# netx90_app register map
File version: 1.0
CPU: CM4 r0p1, little endian, MPU, FPU, 4 interrupt priority bits, 78 interrupts
Registers are 32-bit, read-write, reset 0x0 unless marked. A register's access mark holds for its fields unless they carry their own. Offsets are from the block's base; [hi:lo] are bit positions; {n}, {i} and the like mark numbered series; 'fields as' and 'values as' point back to an identical list.

## hif_io_ctrl
Base 0xFF401480
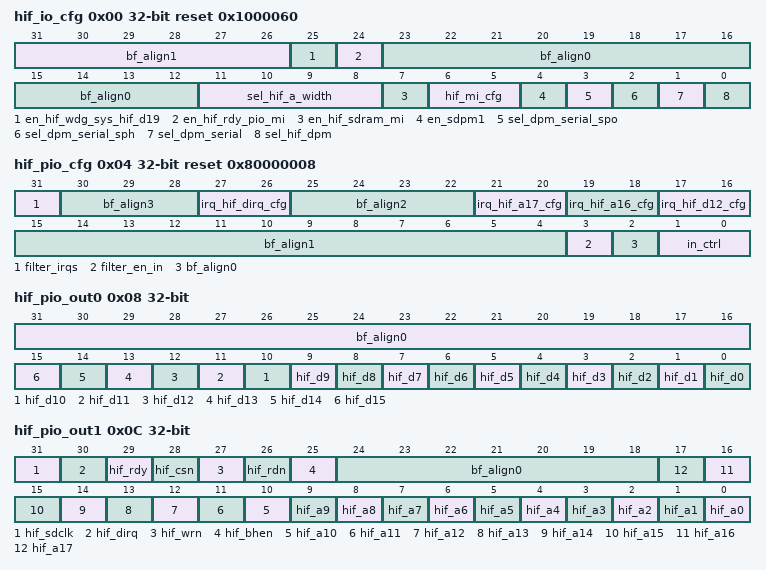
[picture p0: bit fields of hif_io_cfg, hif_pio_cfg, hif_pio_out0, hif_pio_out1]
0x00 hif_io_cfg reset 0x1000060 (reset mask 0x3000FFF) — IO Config Register: Selects of HIF pin multiplexing. See Excel pinning sheet for details. This configuration must be set up according to external netX connection before any access to external logic. This register is protected by the netX access key mechanism; changing this register is only possible by the following sequence: 1.: read out access key from ACCESS_KEY register (ASIC_CTRL address area) 2.: write back access key to ACCESS_KEY register (ASIC_CTRL address area) 3.: write desired value to this register (ASIC_CTRL address area) Attention: Be very careful programming this register. False settings may cause permanent damage on netX or devices connected to HIF-IOs.
  [31:26] bf_align1 — bitField alignment value for aeabi compatibility
  [25] en_hif_wdg_sys_hif_d19 — Obsolete for netX90, removed by regdef filter script. Enable 'wdg_active'/'WDGACT'-signal of netX system watchdog on HIF_D19. # default 0 When this bit is set HIF_D19 will be set to output mode and provide watchdog-active signal. However this will have no effect when HIF_D19 is used for another function. For parallel DPM with watchdog HIF_D19 must be set to PIO mode inside DPM module. Note: netX system watch can be programmed inside address area 'WATCHDOG'/'NETX_WDG_AREA'.
  [24] en_hif_rdy_pio_mi — Enable HIF_RDY for PIO usage (or other netX MUX function) when the HIF is in memory-mode. Note: This bit must be disabled if HIF_RDY is used as EXT_BUS RDY (extension bus ready input). Note: This bit is ignored if HIF is DPM. Use DPM RDY configuration if HIF_RDY should be used as PIO together with DPM functionality.
  [23:12] bf_align0 — bitField alignment value for aeabi compatibility
  [11:8] sel_hif_a_width — Select HIF MI address width. Selecting smaller address bus width will allow PIO usage on related IOs when not used otherwise (e.g. as SDRAM control signals, see en_hif_sdram_mi). A0 to A11 are always enabled when the HIF MI is enabled by the hif_mi_cfg bits. Following settings are valid for 8 or 16 bit data modes. Please note: - The lower byte of the MI is located on the MII signals (refer to the pinning table). - The upper byte of the MI is located on the lower HIF_D IOs (HIF_D0..7, not on HIF_D8..15). - 32bit data is not supported for netX90 { | | | | | Lines Range IOs Function Comment 0000: 11 2k HIF_A0..10 A0..A10 ext_a0..ext_a10 0001: 12 4k HIF_A0..11 A0..A11 + ext_a11 0010: 13 8k HIF_A0..12 A0..A12 + ext_a12 0011: 14 16k HIF_A0..13 A0..A13 + ext_a13 0100: 15 32k HIF_A0..14 A0..A14 + ext_a14 0101: 16 64k HIF_A0..15 A0..A15 + ext_a15 0110: 17 128k HIF_A0..16 A0..A16 + ext_a16 0111: 18 256k HIF_A0..17 A0..A17 + ext_a17} Following settings are only valid for 8 bit data mode: { | | | | | Lines Range IOs Function Comment 1000 19 512k HIF_A0..17 A0..A17 ext_a0..ext_a17 HIF_D0 A18 ext_a18 1001 20 1M HIF_A0..17 A0..A17 ext_a0..ext_a17 HIF_D0,1 A18,A19 ext_a18,ext_a19 1010 21 2M HIF_A0..17 A0..A17 ext_a0..ext_a17 HIF_D0..2 A18..A20 ext_a18..ext_a20 1011 22 4M HIF_A0..17 A0..A17 ext_a0..ext_a17 HIF_D0..3 A18..A21 ext_a18..ext_a21 1100 23 8M HIF_A0..17 A0..A17 ext_a0..ext_a17 HIF_D0..4 A18..A22 ext_a18..ext_a22 1101 24 16M HIF_A0..17 A0..A17 ext_a0..ext_a17 HIF_D0..5 A18..A23 ext_a18..ext_a23 1110 25 32M HIF_A0..17 A0..A17 ext_a0..ext_a17 HIF_D0..6 A18..A24 ext_a18..ext_a24 }
  [7] en_hif_sdram_mi — Enable HIF IOs for SDRAM Memory Interface configuration. HIF-SDRAM Chip-Select is generated on HIF_CSN when this bit is set. ExtBus Chip-Select area 0 is not available then. Ready-Signal for ExtBus is never available when SDRAM is enabled here. If enabled following IOs are used for SDRAM (netX90, partial shared with SRAM/FLASH ctrl signals): { | | netX90 IO Function Comment HIF_A0..12 SD_A0..12 Shared SDRAM/FLASH/SRAM address lines, small SDRAM devices do not need all lines (sel_hif_a_width). MII1_RXER SD_D0 Lower data byte bit 0. Shared SDRAM/FLASH/SRAM data lines. MII1_CRS SD_D1 Lower data byte bit 1. Shared SDRAM/FLASH/SRAM data lines. MII1_COL SD_D2 Lower data byte bit 2. Shared SDRAM/FLASH/SRAM data lines. PHY0_LED_LINK_IN SD_D3 Lower data byte bit 3. Shared SDRAM/FLASH/SRAM data lines. PHY1_LED_LINK_IN SD_D4 Lower data byte bit 4. Shared SDRAM/FLASH/SRAM data lines. MII0_TXEN SD_D5 Lower data byte bit 5. Shared SDRAM/FLASH/SRAM data lines. MII0_COL SD_D6 Lower data byte bit 6. Shared SDRAM/FLASH/SRAM data lines. MII0_CRS SD_D7 Lower data byte bit 7. Shared SDRAM/FLASH/SRAM data lines. HIF_D0..7 SD_D8..15 Upper data byte, Shared SDRAM/FLASH/SRAM data lines. HIF_A13..14 SD_BA0..1 Only during SDRAM access, usable as FLASH/SRAM A13..14 simultaneously. HIF_A15 SD_RASN Only during SDRAM access, usable as FLASH/SRAM A15 simultaneously. HIF_A16 SD_CASN Only during SDRAM access, usable as FLASH/SRAM A16 simultaneously. HIF_A17 SD_DQM0N Only during SDRAM access, usable as FLASH/SRAM A17 simultaneously. HIF_BHEN SD_DQM1N Only during SDRAM access, usable as FLASH/SRAM BHEN simultaneously. HIF_WRN SD_WEN Only during SDRAM access, usable as FLASH/SRAM nWR simultaneously. HIF_CSN SD_CSN ExtBus CS0 not available HIF_RDY SD_CKE ExtBus Ready never available when SDRAM enabled HIF_SDCLK SD_CLK HIF SDRAM clock, ExtBus CS2 not available } Note: HIF_A lines used for SDRAM will always be driven when this bit is set. This does not depend on programmed value of 'sel_hif_a_width' bit field. However 'sel_hif_a_width' must be set wide enough for SDRAM row and column addressing (depending on used SDRAM device).
  [6:5] hif_mi_cfg — description too long, please enter short description.
  [4] en_sdpm1 — Enables the 2nd serial DPM for netX90. 0: 2nd serial DPM is disabled. 1: 2nd serial DPM is enabled. Note: It is possible to enable the 2nd serial DPM stand-alone or together with the normal DPM in serial mode (i.e. both bits 'sel_hif_dpm' and 'sel_dpm_serial' set). It is not possible to use the 2nd serial DPM together with the first DPM in parallel mode as they use the same IOs (the 2nd DPM does not provide the parallel mode). Note: The mode of the 2nd serial DPM is same as for the first DPM (programmed by the bits 'sel_dpm_serial_spo' and 'sel_dpm_serial_sph')
  [3] sel_dpm_serial_spo — serial DPM mode SPI clock polarity selection (sel_hif_dpm and sel_dpm_serial must be set) 0: Serial clock idle state is low. 1: Serial clock idle state is high.
  [2] sel_dpm_serial_sph — serial DPM mode SPI clock phase selection (sel_hif_dpm and sel_dpm_serial must be set) 0: Serial data sampling on first serial clock edge. 1: Serial data sampling on second serial clock edge.
  [1] sel_dpm_serial — serial (SPI) DPM mode selection (ignored if sel_hif_dpm not set). There are 2 independent serial DPM interfaces for netX90. They can be used together, e.g. one for cyclic and one for acyclic data) or stand-alone. The 1st sDPM (sDPM0) can always be used together with external memory (even 16bit mode). sDPM1 can only be used with an 8 bit MI. The pinning positions of serial DPM interfaces are provided by the main pinning table: The pinning-functions 'dpm0_spi*' represent sDPM0, pinning-functions 'dpm1_spi*' represent sDPM1. Note: For parallel DPM, the IRQ signals to the host are located on HIF_DIRQ and HIF_SDCLK (DPM0 only). When external SDRAM is used (en_hif_sdram_mi) the IRQ on HIF_SDCLK is not available). For serial DPM the IRQs are located on different IOs (refer to main pinning table).
  [0] sel_hif_dpm — select DPM mode for HIF (serial or parallel) Note: For parallel DPM IO configuration use config registers in address area DPM. Note: Parallel DPM fast/service IRQ functionality (SIRQ/FIQ) on HIF_SDCLK is controlled by en_hif_sdram_mi bit Note: For parallel DPM host IRQs can be generated on HIF_DIRQ and HIF_SDCLK IOs. Note: For parallel DPM HIF PIO function muse be configured inside 'dpm_pio_cfg' registers for all HIF IOs.
0x04 hif_pio_cfg reset 0x80000008 (reset mask 0x8C3F000B) — HIF PIO Mode configuration register.
  [31] filter_irqs — Filtering of HIF PIO inputs for IRQ generation. By default filtering is applied on HIF PIO inputs before IRQ generation. 0 Spikes on PIOs will not be suppressed for HIF PIO IRQ generation. 1 Spikes up to 10ns on HIF PIOs will be suppressed by sample stages for HIF PIO IRQ generation. That causes 10ns additionally IRQ latency.
  [30:28] bf_align3 — bitField alignment value for aeabi compatibility
  [27:26] irq_hif_dirq_cfg — HIF_DIRQ IRQ input configuration { | Mode Function 00 low level active IRQ 01 high level active IRQ 10 falling edge active IRQ 11 rising edge active IRQ } For IRQ usage this IO should be in PIO input mode, (programmed in the 'hif_io_cfg' register or PIO-configuration registers of the DPM module). For input its PIO output enable must be programmed to '0'. Spikes on related PIO can be suppressed by 'filter_irqs' bit. Note: HIF PIO IRQs can be assigned and monitored in hif_pio_irq registers further down. Note: The HIF IRQ input bit fields are reordered since netx51/52
  [25:22] bf_align2 — bitField alignment value for aeabi compatibility
  [21:20] irq_hif_a17_cfg — HIF_A17 IRQ input configuration For coding refer to irq_hif_dirq_cfg bit-field.
  [19:18] irq_hif_a16_cfg — HIF_A16 IRQ input configuration For coding refer to irq_hif_dirq_cfg bit-field.
  [17:16] irq_hif_d12_cfg — HIF_D12 (DPM_SPI_DIRQ/SPM_DIRQ) IRQ input configuration For coding refer to irq_hif_dirq_cfg bit-field.
  [15:4] bf_align1 — bitField alignment value for aeabi compatibility
  [3] filter_en_in — HIF PIO Input sampling enable (EN_IN) filter. 0 Spikes will not be suppressed for EN_IN. 1 Spikes up to 10ns will be suppressed by HIF PIO EN_IN sample stages. Note: Spike suppression can only done for EN_IN input. There is no spike suppression for data inputs of 'hif_pio_in0,1' registers.
  [2] bf_align0 — bitField alignment value for aeabi compatibility
  [1:0] in_ctrl — HIF PIO Input sampling mode. HIF input status registers hif_pio_in0,1 can be configured by programming these bits. { | Mode Function 00 pio_in registers show HIF IO states sampled at power-on-reset release. 01 HIF IO states are sampled continuously (each netX system clock cycle) 10 HIF IO states are sampling is done each system clock cycle when enable signal EN_IN (MMIO-function) level is low. 11 HIF IO states are sampling is done each system clock cycle when enable signal EN_IN (MMIO-function) level is high. others reserved } Note: Settings 00 to 11 are netX 50 compatible (netX 50 register DPM_ARM_IO_MODE1.IN_CONTROL). Note: Power-on-reset states will not be lost when 'in_ctrl' is set to a value not 0. Note: Power-on-reset states can be used to read pullup/down configuration of HIF-IOs. However, be careful using reset sampled values of HIF data lines when SDRAM is connected: When Reset is done during SDRAM read access, SDRAM device will keep driving data bus. Pull-up/down values will be overdriven by that.
0x08 hif_pio_out0 (reset mask 0xFFFF) — HIF PIO Output State Configuration Register 0. All unused HIF signals can be used as PIOs. IOs will be driven to the programmed state if appropriate enable bit is set in hif_pio_oe0 register. PIO mode driving of HIF-IOs used in current HIF/EXT_BUS Memory Interface configuration is not possible. ----------------------- Note: This register can be read or written by 8, 16 or 32 bit access.
  [31:16] bf_align0 — bitField alignment value for aeabi compatibility
  [n] hif_d{n} (n=0..15) — PIO output drive level of HIF_D{n} signal.
0x0C hif_pio_out1 (reset mask 0xFE03FFFF) — HIF PIO Output State Configuration Register 1. All unused HIF signals can be used as PIOs. IOs will be driven to the programmed state if appropriate enable bit is set in hif_pio_oe1 register. PIO mode driving of HIF-IOs used in current HIF/EXT_BUS Memory Interface configuration is not possible. ----------------------- Note: This register can be read or written by 8, 16 or 32 bit access.
  [31] hif_sdclk — PIO output drive level of HIF_SDCLK signal.
  [30] hif_dirq — PIO output drive level of HIF_DIRQ signal.
  [29] hif_rdy — PIO output drive level of HIF_RDY signal.
  [28] hif_csn — PIO output drive level of HIF_CSN signal.
  [27] hif_wrn — PIO output drive level of HIF_WRN signal.
  [26] hif_rdn — PIO output drive level of HIF_RDN signal.
  [25] hif_bhen — PIO output drive level of HIF_BHEN signals.
  [24:18] bf_align0 — bitField alignment value for aeabi compatibility
  [n] hif_a{n} (n=0..17) — PIO output drive level of HIF_A{n} signal.
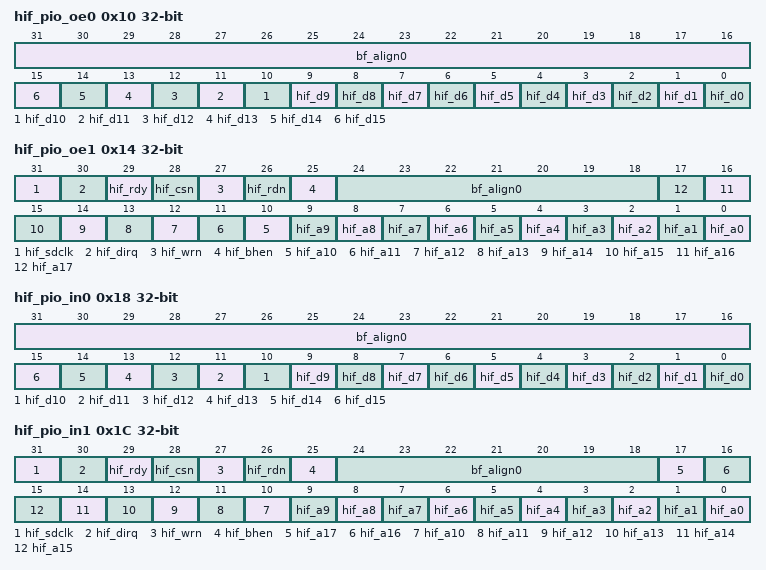
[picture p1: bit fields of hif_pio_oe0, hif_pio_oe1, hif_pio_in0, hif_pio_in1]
0x10 hif_pio_oe0 (reset mask 0xFFFF) — HIF PIO Output Enable Configuration Register 0. All unused HIF signals can be used as PIOs. IOs will be driven to the output state programmed in in hif_pio_out0 register. PIO mode driving of HIF-IOs used in current HIF/EXT_BUS Memory Interface configuration is not possible. ----------------------- Note: This register can be read or written by 8, 16 or 32 bit access.
  [31:16] bf_align0 — bitField alignment value for aeabi compatibility
  [n] hif_d{n} (n=0..15) — PIO output enable of HIF_D{n} signal.
0x14 hif_pio_oe1 (reset mask 0xFE03FFFF) — HIF PIO Output Enable Configuration Register 1. All unused HIF signals can be used as PIOs. IOs will be driven to the output state programmed in in hif_pio_out1 register. PIO mode driving of HIF-IOs used in current HIF/EXT_BUS Memory Interface configuration is not possible. ----------------------- Note: This register can be read or written by 8, 16 or 32 bit access.
  [31] hif_sdclk — PIO output enable of HIF_SDCLK signal.
  [30] hif_dirq — PIO output enable of HIF_DIRQ signal.
  [29] hif_rdy — PIO output enable of HIF_RDY signal.
  [28] hif_csn — PIO output enable of HIF_CSN signal.
  [27] hif_wrn — PIO output enable of HIF_WRN signal.
  [26] hif_rdn — PIO output enable of HIF_RDN signal.
  [25] hif_bhen — PIO output enable of HIF_BHEN signals.
  [24:18] bf_align0 — bitField alignment value for aeabi compatibility
  [n] hif_a{n} (n=0..17) — PIO output enable of HIF_A{n} signal.
0x18 hif_pio_in0 ro (reset mask 0xFFFF) — HIF PIO Input State Register 0. IO input states can be read here regardless whether IO is used in current HIF/EXT_BUS Memory Interface configuration. HIF IO sampling behaviour can be programmed by 'in_ctrl' bits of 'hif_pio_cfg' register.
  [31:16] bf_align0 — bitField alignment value for aeabi compatibility
  [n] hif_d{n} (n=0..15) — PIO input state of HIF_D{n} signal.
0x1C hif_pio_in1 ro (reset mask 0xFE03FFFF) — HIF PIO Input State Register 1. IO input states can be read here regardless whether IO is used in current HIF/EXT_BUS Memory Interface configuration.
  [31] hif_sdclk — PIO input state of HIF_SDCLK signal.
  [30] hif_dirq — PIO input state of HIF_DIRQ signal.
  [29] hif_rdy — PIO input state of HIF_RDY signal.
  [28] hif_csn — PIO input state of HIF_CSN signal.
  [27] hif_wrn — PIO input state of HIF_WRN signal.
  [26] hif_rdn — PIO input state of HIF_RDN signal.
  [25] hif_bhen — PIO input state of HIF_BHEN signal.
  [24:18] bf_align0 — bitField alignment value for aeabi compatibility
  [17] hif_a17 — PIO input state of HIF_A17 signal
  [16] hif_a16 — PIO input state of HIF_A16 signal
  [n] hif_a{n} (n=0..15) — PIO input state of HIF_A{n} signal.
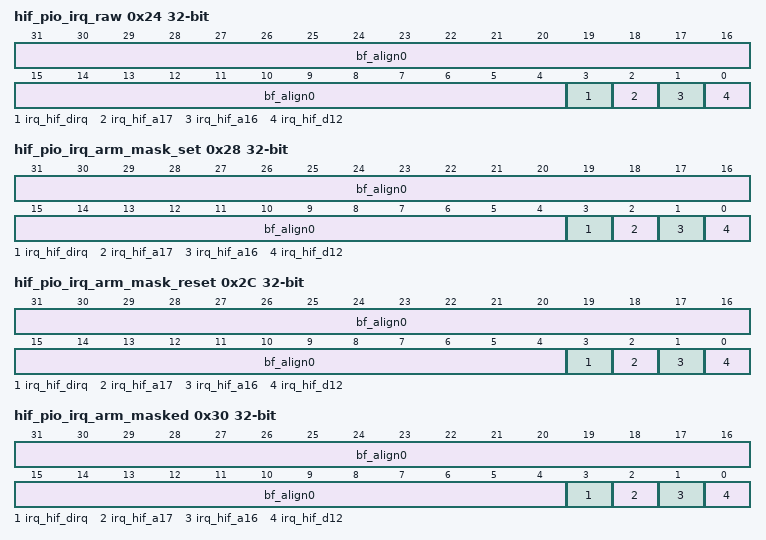
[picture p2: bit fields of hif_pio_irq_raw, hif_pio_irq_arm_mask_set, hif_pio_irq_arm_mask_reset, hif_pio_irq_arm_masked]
0x24 hif_pio_irq_raw ro (reset mask 0xF) — HIF PIO Raw (before masking) IRQ Status Register. If bit is set, the according interrupt is asserted. Interrupt status can be cleared by writing ones to this register. Each IRQ source can be assigned either to xPIC or to ARM (or to both) by the following registers. IRQ clearing has lower priority than IRQ set when done simultaneously. Note: Spikes up to 10ns will be suppressed by HIF PIO IRQ sample stages. Note: HIF PIO interrupt function can be configured in the hif_pio_cfg register. Note: HIF PIO IRQs are combined with DPM IRQs and Handshake-Cell (HANDSHACKE_CTRL) IRQs. Note: The bits of this register are reordered since netx51/52.
  [31:4] bf_align0 — bitField alignment value for aeabi compatibility
  [3] irq_hif_dirq — HIF_DIRQ IRQ
  [2] irq_hif_a17 — HIF_A17 IRQ
  [1] irq_hif_a16 — HIF_A16 IRQ
  [0] irq_hif_d12 — HIF_D12 (DPM_SPI_DIRQ/SPM_DIRQ)
0x28 hif_pio_irq_arm_mask_set (reset mask 0xF) — HIF PIO Interrupt Mask Register for netX internal ARM. Write access with '1' sets interrupt mask bit (enables interrupt request for corresponding interrupt source). Write access with '0' does not influence this bit. Read access shows actual interrupt mask. If bit is set, the according interrupt will activate the IRQ for netX internal ARM. Interrupt status can be cleared by writing ones to the hif_pio_irq_raw register. To release IRQ for netX internal ARM without clearing interrupt in module, reset according mask bit to 0. Note: Spikes up to 10ns will be suppressed by HIF PIO IRQ sample stages. Note: HIF PIO interrupt function can be configured in the hif_pio_cfg register. Note: HIF PIO IRQs are combined with DPM IRQs and Handshake-Cell (HANDSHACKE_CTRL) IRQs.
  fields as hif_pio_irq_raw
0x2C hif_pio_irq_arm_mask_reset (reset mask 0xF) — HIF PIO Interrupt Mask Reset Register for netX internal ARM. Write access with '1' resets interrupt mask bit (disables interrupt request for corresponding interrupt source). Write access with '0' does not influence this bit. Read access shows actual interrupt mask. If bit is set, the according interrupt will activate the IRQ for netX internal ARM if asserted. Interrupt status can be cleared by writing ones to the hif_pio_irq_raw register. To release IRQ for netX internal ARM without clearing interrupt in module, reset according mask bit to 0. Note: Spikes up to 10ns will be suppressed by HIF PIO IRQ sample stages. Note: HIF PIO interrupt function can be configured in the hif_pio_cfg register. Note: HIF PIO IRQs are combined with DPM IRQs and Handshake-Cell (HANDSHACKE_CTRL) IRQs.
  fields as hif_pio_irq_raw
0x30 hif_pio_irq_arm_masked ro (reset mask 0xF) — HIF PIO Masked Interrupt Status Register for netX internal ARM. If bit is set, if the according mask bit is set in hif_pio_irq_arm_mask-register and the according interrupt is asserted. IRQ for netX internal ARM signal is asserted if at least one bit is set here. Interrupt status can be cleared by writing ones to the hif_pio_irq_raw register. To release IRQ for netX internal ARM signal without clearing interrupt in module, reset according mask bit to 0. Note: Spikes up to 10ns will be suppressed by HIF PIO IRQ sample stages. Note: HIF PIO interrupt function can be configured in the hif_pio_cfg register. Note: HIF PIO IRQs are combined with DPM IRQs and Handshake-Cell (HANDSHACKE_CTRL) IRQs.
  fields as hif_pio_irq_raw
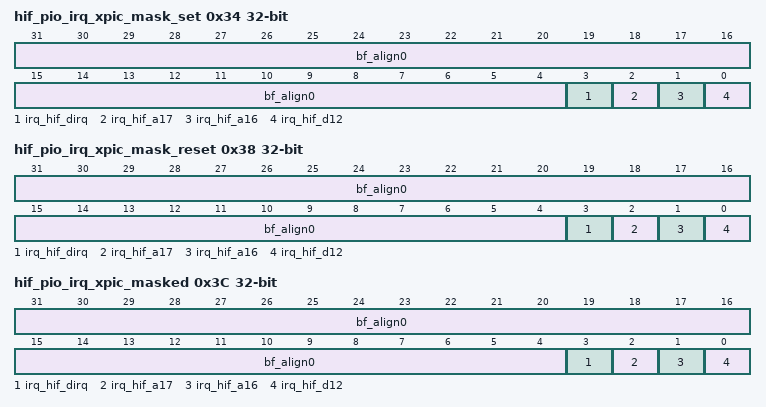
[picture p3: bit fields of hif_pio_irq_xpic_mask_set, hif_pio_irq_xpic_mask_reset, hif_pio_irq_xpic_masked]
0x34 hif_pio_irq_xpic_mask_set (reset mask 0xF) — HIF PIO Interrupt Mask Register for netX internal xPIC. Write access with '1' sets interrupt mask bit (enables interrupt request for corresponding interrupt source). Write access with '0' does not influence this bit. Read access shows actual interrupt mask. If bit is set, the according interrupt will activate the IRQ for netX internal xPIC. Interrupt status can be cleared by writing ones to the hif_pio_irq_raw register. To release IRQ for netX internal xPIC without clearing interrupt in module, reset according mask bit to 0. Note: Spikes up to 10ns will be suppressed by HIF PIO IRQ sample stages. Note: HIF PIO interrupt function can be configured in the hif_pio_cfg register. Note: HIF PIO IRQs are combined with DPM IRQs and Handshake-Cell (HANDSHACKE_CTRL) IRQs.
  fields as hif_pio_irq_raw
0x38 hif_pio_irq_xpic_mask_reset (reset mask 0xF) — HIF PIO Interrupt Mask Reset Register for netX internal xPIC. Write access with '1' resets interrupt mask bit (disables interrupt request for corresponding interrupt source). Write access with '0' does not influence this bit. Read access shows actual interrupt mask. If bit is set, the according interrupt will activate the IRQ for netX internal xPIC if asserted. Interrupt status can be cleared by writing ones to the hif_pio_irq_raw register. To release IRQ for netX internal xPIC without clearing interrupt in module, reset according mask bit to 0. Note: Spikes up to 10ns will be suppressed by HIF PIO IRQ sample stages. Note: HIF PIO interrupt function can be configured in the hif_pio_cfg register. Note: HIF PIO IRQs are combined with DPM IRQs and Handshake-Cell (HANDSHACKE_CTRL) IRQs.
  fields as hif_pio_irq_raw
0x3C hif_pio_irq_xpic_masked ro (reset mask 0xF) — HIF PIO Masked Interrupt Status Register for netX internal xPIC. If bit is set, if the according mask bit is set in hif_pio_irq_xpic_mask-register and the according interrupt is asserted. IRQ for netX internal xPIC signal is asserted if at least one bit is set here. Interrupt status can be cleared by writing ones to the hif_pio_irq_raw register. To release IRQ for netX internal xPIC signal without clearing interrupt in module, reset according mask bit to 0. Note: Spikes up to 10ns will be suppressed by HIF PIO IRQ sample stages. Note: HIF PIO interrupt function can be configured in the hif_pio_cfg register. Note: HIF PIO IRQs are combined with DPM IRQs and Handshake-Cell (HANDSHACKE_CTRL) IRQs.
  fields as hif_pio_irq_raw
